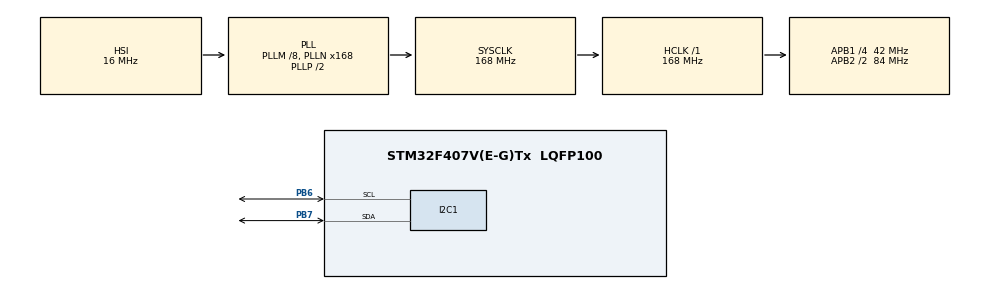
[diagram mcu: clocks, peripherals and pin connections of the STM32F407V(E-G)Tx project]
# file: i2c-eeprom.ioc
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Mcu.Family=STM32F4
Mcu.Name=STM32F407V(E-G)Tx
Mcu.Package=LQFP100
NVIC.PriorityGroup=NVIC_PRIORITYGROUP_4
PA13.Mode=Serial_Wire
PA13.Signal=SYS_JTMS-SWDIO
PA14.Mode=Serial_Wire
PA14.Signal=SYS_JTCK-SWCLK
PB6.Mode=I2C
PB6.Signal=I2C1_SCL
PB7.Mode=I2C
PB7.Signal=I2C1_SDA
ProjectManager.HeapSize=0x200
ProjectManager.StackSize=0x400
ProjectManager.TargetToolchain=MDK-ARM V5.27
RCC.48MHZClocksFreq_Value=84000000
RCC.AHBFreq_Value=168000000
RCC.APB1CLKDivider=RCC_HCLK_DIV4
RCC.APB1Freq_Value=42000000
RCC.APB1TimFreq_Value=84000000
RCC.APB2CLKDivider=RCC_HCLK_DIV2
RCC.APB2Freq_Value=84000000
RCC.APB2TimFreq_Value=168000000
RCC.CortexFreq_Value=168000000
RCC.HCLKFreq_Value=168000000
RCC.HSE_VALUE=25000000
RCC.HSI_VALUE=16000000
RCC.LSE_VALUE=32768
RCC.PLLM=8
RCC.PLLN=168
RCC.SYSCLKFreq_VALUE=168000000
RCC.SYSCLKSource=RCC_SYSCLKSOURCE_PLLCLK
RCC.VCOOutputFreq_Value=336000000
board=custom

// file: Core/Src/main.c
/* USER CODE BEGIN Header */
/**
  ******************************************************************************
  * @file           : main.c
  * @brief          : Main program body
  ******************************************************************************
  * @attention
  *
  * <h2><center>&copy; Copyright (c) 2021 STMicroelectronics.
  * All rights reserved.</center></h2>
  *
  * This software component is licensed by ST under BSD 3-Clause license,
  * the "License"; You may not use this file except in compliance with the
  * License. You may obtain a copy of the License at:
  *                        opensource.org/licenses/BSD-3-Clause
  *
  ******************************************************************************
  */
/* USER CODE END Header */
#include "main.h"
#include "i2c.h"
#include "gpio.h"

/* USER CODE BEGIN Includes */
#include "stdio.h"
#include "string.h"
/* USER CODE END Includes */

void SystemClock_Config(void);
/* USER CODE BEGIN PFP */
    int i = 0;
    unsigned char Write_Data[256];
    unsigned char Read_Data[256];
    char str[100];
/* USER CODE END PFP */

int main(void)
{

  /* MCU Configuration--------------------------------------------------------*/

  /* Reset of all peripherals, Initializes the Flash interface and the Systick. */
  HAL_Init();

  /* Configure the system clock */
  SystemClock_Config();

  /* Initialize all configured peripherals */
  MX_GPIO_Init();
  MX_I2C1_Init();
  /* USER CODE BEGIN 2 */
    memset(Write_Data,0xAA,256);
    memset(Read_Data,0xAA,256);

    if(HAL_I2C_IsDeviceReady(&hi2c1,0xA0,1,1000) != HAL_OK)
    {
        while(1);
    }

//    for(i = 0; i < 256; i++)
//        Write_Data[i] = i;
//
//    HAL_Delay(1000);
//    if(HAL_I2C_Mem_Write(&hi2c1,0xA0,0,1,Write_Data,8,1000) != HAL_OK)
//    {
//        sprintf(str,"\r\nWrite Error");
////        HAL_UART_Transmit(&huart2,str,strlen(str),1000);
//        while(1);
//    }
//    sprintf(str,"\r\n======================================");
////    HAL_UART_Transmit(&huart2,str,strlen(str),1000);
//
//    for(i = 0; i < 10; i++)
//    {
//        sprintf(str,"\r\nRead_Data[%03d] = %03d",i,Read_Data[i]);
////        HAL_UART_Transmit(&huart2,str,strlen(str),1000);
//    }
//
//    sprintf(str,"\r\n======================================");
////    HAL_UART_Transmit(&huart2,str,strlen(str),1000);

    HAL_Delay(1000);
    if(HAL_I2C_Mem_Read(&hi2c1,0xA0,0,1,Read_Data,8,1000) != HAL_OK)
    {
        sprintf(str,"\r\nRead Error");
//        HAL_UART_Transmit(&huart2,str,strlen(str),1000);
        while(1);
    }

    for(i = 0; i < 10; i++)
    {
        sprintf(str,"\r\nRead_Data[%03d] = %03d",i,Read_Data[i]);
//        HAL_UART_Transmit(&huart2,str,strlen(str),1000);
    }

    sprintf(str,"\r\n======================================");
//    HAL_UART_Transmit(&huart2,str,strlen(str),1000);
  /* USER CODE END 2 */

  /* Infinite loop */
  while (1)
  {

  }
}

void SystemClock_Config(void)
{
  RCC_OscInitTypeDef RCC_OscInitStruct = {0};
  RCC_ClkInitTypeDef RCC_ClkInitStruct = {0};

  /** Configure the main internal regulator output voltage
  */
  __HAL_RCC_PWR_CLK_ENABLE();
  __HAL_PWR_VOLTAGESCALING_CONFIG(PWR_REGULATOR_VOLTAGE_SCALE1);
  /** Initializes the RCC Oscillators according to the specified parameters
  * in the RCC_OscInitTypeDef structure.
  */
  RCC_OscInitStruct.OscillatorType = RCC_OSCILLATORTYPE_HSI;
  RCC_OscInitStruct.HSIState = RCC_HSI_ON;
  RCC_OscInitStruct.HSICalibrationValue = RCC_HSICALIBRATION_DEFAULT;
  RCC_OscInitStruct.PLL.PLLState = RCC_PLL_ON;
  RCC_OscInitStruct.PLL.PLLSource = RCC_PLLSOURCE_HSI;
  RCC_OscInitStruct.PLL.PLLM = 8;
  RCC_OscInitStruct.PLL.PLLN = 168;
  RCC_OscInitStruct.PLL.PLLP = RCC_PLLP_DIV2;
  RCC_OscInitStruct.PLL.PLLQ = 4;
  if (HAL_RCC_OscConfig(&RCC_OscInitStruct) != HAL_OK)
  {
    Error_Handler();
  }
  /** Initializes the CPU, AHB and APB buses clocks
  */
  RCC_ClkInitStruct.ClockType = RCC_CLOCKTYPE_HCLK|RCC_CLOCKTYPE_SYSCLK
                              |RCC_CLOCKTYPE_PCLK1|RCC_CLOCKTYPE_PCLK2;
  RCC_ClkInitStruct.SYSCLKSource = RCC_SYSCLKSOURCE_PLLCLK;
  RCC_ClkInitStruct.AHBCLKDivider = RCC_SYSCLK_DIV1;
  RCC_ClkInitStruct.APB1CLKDivider = RCC_HCLK_DIV4;
  RCC_ClkInitStruct.APB2CLKDivider = RCC_HCLK_DIV2;

  if (HAL_RCC_ClockConfig(&RCC_ClkInitStruct, FLASH_LATENCY_5) != HAL_OK)
  {
    Error_Handler();
  }
}

void Error_Handler(void)
{
  __disable_irq();
  while (1)
  {
  }
}

/************************ (C) COPYRIGHT STMicroelectronics *****END OF FILE****/
